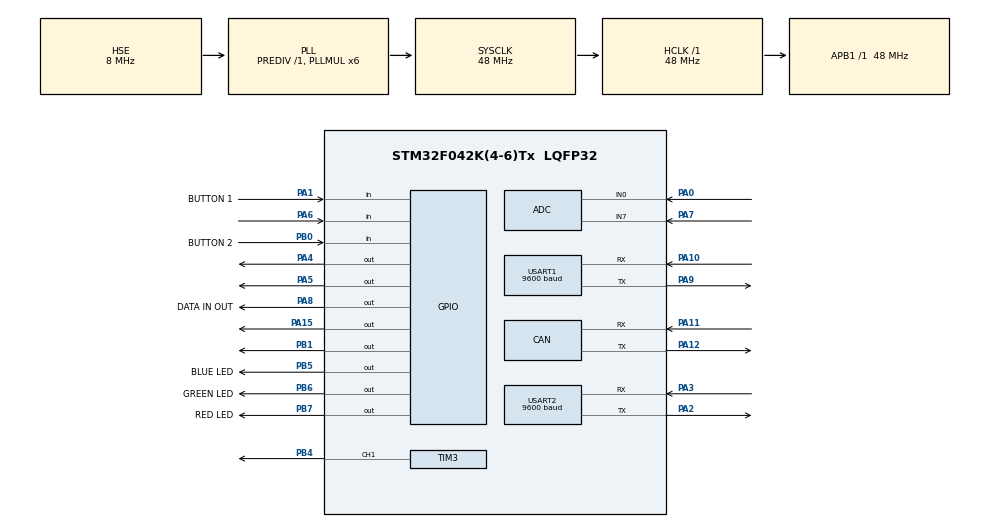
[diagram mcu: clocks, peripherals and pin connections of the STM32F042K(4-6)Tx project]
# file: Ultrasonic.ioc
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ADC.ClockPrescaler=ADC_CLOCK_ASYNC_DIV1
ADC.ContinuousConvMode=ENABLE
ADC.DMAContinuousRequests=ENABLE
ADC.SamplingTime=ADC_SAMPLETIME_28CYCLES_5
CAN.BS1=CAN_BS1_13TQ
CAN.BS2=CAN_BS2_2TQ
CAN.CalculateTimeQuantum=333.3333333333333
Dma.ADC.4.Direction=DMA_PERIPH_TO_MEMORY
Dma.ADC.4.Instance=DMA1_Channel1
Dma.ADC.4.MemDataAlignment=DMA_MDATAALIGN_WORD
Dma.ADC.4.MemInc=DMA_MINC_ENABLE
Dma.ADC.4.Mode=DMA_CIRCULAR
Dma.ADC.4.PeriphDataAlignment=DMA_PDATAALIGN_WORD
Dma.ADC.4.PeriphInc=DMA_PINC_DISABLE
Dma.ADC.4.Priority=DMA_PRIORITY_LOW
Dma.Request0=USART1_RX
Dma.Request1=USART1_TX
Dma.Request2=USART2_RX
Dma.Request3=USART2_TX
Dma.Request4=ADC
Dma.USART1_RX.0.Direction=DMA_PERIPH_TO_MEMORY
Dma.USART1_RX.0.Instance=DMA1_Channel3
Dma.USART1_RX.0.MemDataAlignment=DMA_MDATAALIGN_BYTE
Dma.USART1_RX.0.MemInc=DMA_MINC_ENABLE
Dma.USART1_RX.0.Mode=DMA_NORMAL
Dma.USART1_RX.0.PeriphDataAlignment=DMA_PDATAALIGN_BYTE
Dma.USART1_RX.0.PeriphInc=DMA_PINC_DISABLE
Dma.USART1_RX.0.Priority=DMA_PRIORITY_HIGH
Dma.USART1_TX.1.Direction=DMA_MEMORY_TO_PERIPH
Dma.USART1_TX.1.Instance=DMA1_Channel2
Dma.USART1_TX.1.MemDataAlignment=DMA_MDATAALIGN_BYTE
Dma.USART1_TX.1.MemInc=DMA_MINC_ENABLE
Dma.USART1_TX.1.Mode=DMA_NORMAL
Dma.USART1_TX.1.PeriphDataAlignment=DMA_PDATAALIGN_BYTE
Dma.USART1_TX.1.PeriphInc=DMA_PINC_DISABLE
Dma.USART1_TX.1.Priority=DMA_PRIORITY_HIGH
Dma.USART2_RX.2.Direction=DMA_PERIPH_TO_MEMORY
Dma.USART2_RX.2.Instance=DMA1_Channel5
Dma.USART2_RX.2.MemDataAlignment=DMA_MDATAALIGN_BYTE
Dma.USART2_RX.2.MemInc=DMA_MINC_ENABLE
Dma.USART2_RX.2.Mode=DMA_NORMAL
Dma.USART2_RX.2.PeriphDataAlignment=DMA_PDATAALIGN_BYTE
Dma.USART2_RX.2.PeriphInc=DMA_PINC_DISABLE
Dma.USART2_RX.2.Priority=DMA_PRIORITY_HIGH
Dma.USART2_TX.3.Direction=DMA_MEMORY_TO_PERIPH
Dma.USART2_TX.3.Instance=DMA1_Channel4
Dma.USART2_TX.3.MemDataAlignment=DMA_MDATAALIGN_BYTE
Dma.USART2_TX.3.MemInc=DMA_MINC_ENABLE
Dma.USART2_TX.3.Mode=DMA_NORMAL
Dma.USART2_TX.3.PeriphDataAlignment=DMA_PDATAALIGN_BYTE
Dma.USART2_TX.3.PeriphInc=DMA_PINC_DISABLE
Dma.USART2_TX.3.Priority=DMA_PRIORITY_HIGH
FREERTOS.Tasks01=Task_Ultrasonic,0,128,Start_Ultrasonic_Calculate,Default,NULL,Dynamic,NULL,NULL;Task_Idle,-3,128,Start_Idle,Default,NULL,Dynamic,NULL,NULL;Task_Serial,0,128,Start_Task_Serial,Default,NULL,Dynamic,NULL,NULL;Task_RS485,-3,128,Start_Task_RS485,Default,NULL,Dynamic,NULL,NULL
FREERTOS.configTICK_RATE_HZ=1000
Mcu.Family=STM32F0
Mcu.Name=STM32F042K(4-6)Tx
Mcu.Package=LQFP32
NVIC.DMA1_Channel1_IRQn=true\:0\:0\:false\:false\:true\:true\:false\:true
NVIC.DMA1_Channel2_3_IRQn=true\:0\:0\:false\:false\:true\:true\:false\:true
NVIC.DMA1_Channel4_5_IRQn=true\:0\:0\:false\:false\:true\:true\:false\:true
NVIC.TIM17_IRQn=true\:0\:0\:false\:false\:true\:true\:true\:true
NVIC.TIM1_BRK_UP_TRG_COM_IRQn=true\:0\:0\:false\:false\:true\:false\:false\:true
NVIC.TimeBase=TIM1_BRK_UP_TRG_COM_IRQn
NVIC.TimeBaseIP=TIM1
NVIC.USART1_IRQn=true\:0\:0\:false\:false\:true\:false\:true\:true
NVIC.USART2_IRQn=true\:0\:0\:false\:false\:true\:false\:true\:true
PA0.Mode=IN0
PA0.Signal=ADC_IN0
PA1.GPIO_Label=BUTTON 1
PA1.GPIO_PuPd=GPIO_PULLUP
PA1.Signal=GPIO_Input
PA10.Mode=Asynchronous
PA10.Signal=USART1_RX
PA11.Mode=Master
PA11.Signal=CAN_RX
PA12.Mode=Master
PA12.Signal=CAN_TX
PA13.Mode=Serial_Wire
PA13.Signal=SYS_SWDIO
PA14.Mode=Serial_Wire
PA14.Signal=SYS_SWCLK
PA15.Signal=GPIO_Output
PA2.Mode=Asynchronous
PA2.Signal=USART2_TX
PA3.Mode=Asynchronous
PA3.Signal=USART2_RX
PA4.Signal=GPIO_Output
PA5.Signal=GPIO_Output
PA6.Signal=GPIO_Input
PA7.Mode=IN7
PA7.Signal=ADC_IN7
PA8.GPIO_Label=DATA IN OUT
PA8.Signal=GPIO_Output
PA9.Mode=Asynchronous
PA9.Signal=USART1_TX
PB0.GPIO_Label=BUTTON 2
PB0.Signal=GPIO_Input
PB1.Signal=GPIO_Output
PB4.Signal=S_TIM3_CH1
PB5.GPIO_Label=BLUE LED
PB5.Signal=GPIO_Output
PB6.GPIO_Label=GREEN LED
PB6.Signal=GPIO_Output
PB7.GPIO_Label=RED LED
PB7.Signal=GPIO_Output
PF0-OSC_IN.Mode=HSE-External-Oscillator
PF0-OSC_IN.Signal=RCC_OSC_IN
PF1-OSC_OUT.Mode=HSE-External-Oscillator
PF1-OSC_OUT.Signal=RCC_OSC_OUT
ProjectManager.HeapSize=0x200
ProjectManager.StackSize=0x400
ProjectManager.TargetToolchain=MDK-ARM V5.27
RCC.AHBFreq_Value=48000000
RCC.APB1Freq_Value=48000000
RCC.APB1TimFreq_Value=48000000
RCC.HCLKFreq_Value=48000000
RCC.PLLMUL=RCC_PLL_MUL6
RCC.PLLSourceVirtual=RCC_PLLSOURCE_HSE
RCC.SYSCLKFreq_VALUE=48000000
RCC.SYSCLKSource=RCC_SYSCLKSOURCE_PLLCLK
SH.S_TIM3_CH1.0=TIM3_CH1,PWM Generation1 CH1
TIM17.Period=1000
TIM17.Prescaler=48-1
TIM3.Channel-PWM\ Generation1\ CH1=TIM_CHANNEL_1
TIM3.Period=100-1
TIM3.Prescaler=12-1
TIM3.Pulse-PWM\ Generation1\ CH1=50
USART1.BaudRate=9600
USART1.VirtualMode-Asynchronous=VM_ASYNC
USART2.BaudRate=9600
USART2.VirtualMode-Asynchronous=VM_ASYNC
VP_ADC_TempSens_Input.Mode=IN-TempSens
VP_FREERTOS_VS_CMSIS_V1.Mode=CMSIS_V1
VP_SYS_VS_tim1.Mode=TIM1
VP_TIM17_VS_ClockSourceINT.Mode=Enable_Timer
VP_TIM3_VS_ClockSourceINT.Mode=Internal
board=custom

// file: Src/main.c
/* USER CODE BEGIN Header */
/**
  ******************************************************************************
  * @file           : main.c
  * @brief          : Main program body
  ******************************************************************************
  * @attention
  *
  * <h2><center>&copy; Copyright (c) 2020 STMicroelectronics.
  * All rights reserved.</center></h2>
  *
  * This software component is licensed by ST under Ultimate Liberty license
  * SLA0044, the "License"; You may not use this file except in compliance with
  * the License. You may obtain a copy of the License at:
  *                             www.st.com/SLA0044
  *
  ******************************************************************************
  */
/* USER CODE END Header */
#include "main.h"
#include "cmsis_os.h"
#include "adc.h"
#include "can.h"
#include "dma.h"
#include "tim.h"
#include "usart.h"
#include "gpio.h"

/* USER CODE BEGIN PV */
uint32_t Adc_buffer[3];

/* USER CODE END PV */

void SystemClock_Config(void);
void MX_FREERTOS_Init(void);

int main(void)
{

  /* MCU Configuration--------------------------------------------------------*/

  /* Reset of all peripherals, Initializes the Flash interface and the Systick. */
  HAL_Init();

  /* Configure the system clock */
  SystemClock_Config();

  /* Initialize all configured peripherals */
  MX_GPIO_Init();
  MX_DMA_Init();
  MX_ADC_Init();
  MX_CAN_Init();
  MX_TIM3_Init();
  MX_USART1_UART_Init();
  MX_USART2_UART_Init();
  MX_TIM17_Init();
  /* USER CODE BEGIN 2 */
  HAL_TIM_Base_Start_IT(&htim17);
  HAL_ADC_Start_DMA(&hadc, (uint32_t*)Adc_buffer, 3);
  SetDutyCycle_PWM(50);
  /* USER CODE END 2 */

  /* Call init function for freertos objects (in freertos.c) */
  MX_FREERTOS_Init();
  /* Start scheduler */
  osKernelStart();

  /* We should never get here as control is now taken by the scheduler */
  /* Infinite loop */
  while (1)
  {

  }
}

void SystemClock_Config(void)
{
  RCC_OscInitTypeDef RCC_OscInitStruct = {0};
  RCC_ClkInitTypeDef RCC_ClkInitStruct = {0};
  RCC_PeriphCLKInitTypeDef PeriphClkInit = {0};

  /** Initializes the RCC Oscillators according to the specified parameters
  * in the RCC_OscInitTypeDef structure.
  */
  RCC_OscInitStruct.OscillatorType = RCC_OSCILLATORTYPE_HSI14|RCC_OSCILLATORTYPE_HSE;
  RCC_OscInitStruct.HSEState = RCC_HSE_ON;
  RCC_OscInitStruct.HSI14State = RCC_HSI14_ON;
  RCC_OscInitStruct.HSI14CalibrationValue = 16;
  RCC_OscInitStruct.PLL.PLLState = RCC_PLL_ON;
  RCC_OscInitStruct.PLL.PLLSource = RCC_PLLSOURCE_HSE;
  RCC_OscInitStruct.PLL.PLLMUL = RCC_PLL_MUL6;
  RCC_OscInitStruct.PLL.PREDIV = RCC_PREDIV_DIV1;
  if (HAL_RCC_OscConfig(&RCC_OscInitStruct) != HAL_OK)
  {
    Error_Handler();
  }
  /** Initializes the CPU, AHB and APB buses clocks
  */
  RCC_ClkInitStruct.ClockType = RCC_CLOCKTYPE_HCLK|RCC_CLOCKTYPE_SYSCLK
                              |RCC_CLOCKTYPE_PCLK1;
  RCC_ClkInitStruct.SYSCLKSource = RCC_SYSCLKSOURCE_PLLCLK;
  RCC_ClkInitStruct.AHBCLKDivider = RCC_SYSCLK_DIV1;
  RCC_ClkInitStruct.APB1CLKDivider = RCC_HCLK_DIV1;

  if (HAL_RCC_ClockConfig(&RCC_ClkInitStruct, FLASH_LATENCY_1) != HAL_OK)
  {
    Error_Handler();
  }
  PeriphClkInit.PeriphClockSelection = RCC_PERIPHCLK_USART1;
  PeriphClkInit.Usart1ClockSelection = RCC_USART1CLKSOURCE_PCLK1;
  if (HAL_RCCEx_PeriphCLKConfig(&PeriphClkInit) != HAL_OK)
  {
    Error_Handler();
  }
}

void Error_Handler(void)
{
  /* USER CODE BEGIN Error_Handler_Debug */
  /* User can add his own implementation to report the HAL error return state */
  NVIC_SystemReset();
  while (1)
  {
    /* code */
  }

  /* USER CODE END Error_Handler_Debug */
}

/************************ (C) COPYRIGHT STMicroelectronics *****END OF FILE****/

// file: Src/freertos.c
/* USER CODE BEGIN Header */
/* USER CODE END Header */

#include "FreeRTOS.h"
#include "task.h"
#include "main.h"
#include "cmsis_os.h"

/* USER CODE BEGIN Includes */
#include "distance.h"
#include "gpio.h"
#include "usart.h"
#include "runtask.h"
// #include "FLASH_PAGE.h"
/* USER CODE END Includes */

osThreadId Task_UltrasonicHandle;
osThreadId Task_IdleHandle;
osThreadId Task_SerialHandle;
osThreadId Task_RS485Handle;

/* USER CODE BEGIN FunctionPrototypes */
float map(float x, float in_min, float in_max, float out_min, float out_max);

/* USER CODE END FunctionPrototypes */

void MX_FREERTOS_Init(void); /* (MISRA C 2004 rule 8.1) */

/* GetIdleTaskMemory prototype (linked to static allocation support) */
void vApplicationGetIdleTaskMemory( StaticTask_t **ppxIdleTaskTCBBuffer, StackType_t **ppxIdleTaskStackBuffer, uint32_t *pulIdleTaskStackSize );

/* USER CODE BEGIN GET_IDLE_TASK_MEMORY */
static StaticTask_t xIdleTaskTCBBuffer;
static StackType_t xIdleStack[configMINIMAL_STACK_SIZE];

void vApplicationGetIdleTaskMemory(StaticTask_t **ppxIdleTaskTCBBuffer,
                                   StackType_t **ppxIdleTaskStackBuffer,
                                   uint32_t *pulIdleTaskStackSize)
{
  *ppxIdleTaskTCBBuffer = &xIdleTaskTCBBuffer;
  *ppxIdleTaskStackBuffer = &xIdleStack[0];
  *pulIdleTaskStackSize = configMINIMAL_STACK_SIZE;
  /* place for user code */
}
/* USER CODE END GET_IDLE_TASK_MEMORY */

void MX_FREERTOS_Init(void) {

  /* Create the thread(s) */
  /* definition and creation of Task_Ultrasonic */
  osThreadDef(Task_Ultrasonic, Start_Ultrasonic_Calculate, osPriorityNormal, 0, 128);
  Task_UltrasonicHandle = osThreadCreate(osThread(Task_Ultrasonic), NULL);

  /* definition and creation of Task_Idle */
  osThreadDef(Task_Idle, Start_Idle, osPriorityIdle, 0, 128);
  Task_IdleHandle = osThreadCreate(osThread(Task_Idle), NULL);

  /* definition and creation of Task_Serial */
  osThreadDef(Task_Serial, Start_Task_Serial, osPriorityNormal, 0, 128);
  Task_SerialHandle = osThreadCreate(osThread(Task_Serial), NULL);

  /* definition and creation of Task_RS485 */
  osThreadDef(Task_RS485, Start_Task_RS485, osPriorityIdle, 0, 128);
  Task_RS485Handle = osThreadCreate(osThread(Task_RS485), NULL);

  /* USER CODE BEGIN RTOS_THREADS */
  /* add threads, ... */
  Init_filter();

  /* USER CODE END RTOS_THREADS */

}

/* USER CODE BEGIN Application */

float map(float x, float in_min, float in_max, float out_min, float out_max)
{
  return (x - in_min) * (out_max - out_min) / (in_max - in_min) + out_min;
}

/* USER CODE END Application */

/************************ (C) COPYRIGHT STMicroelectronics *****END OF FILE****/
